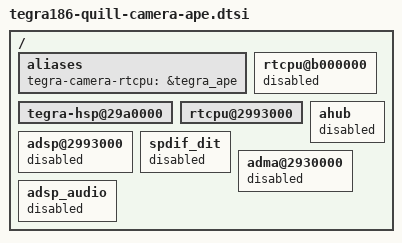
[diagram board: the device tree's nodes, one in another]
/*
 * tegra186-quill-camera-ape.dtsi: Quill APE for camera dtsi.
 *
 * Copyright (c) 2016, NVIDIA CORPORATION.  All rights reserved.
 *
 * This program is free software; you can redistribute it and/or modify
 * it under the terms of the GNU General Public License as published by
 * the Free Software Foundation; version 2 of the License.
 *
 * This program is distributed in the hope that it will be useful, but WITHOUT
 * ANY WARRANTY; without even the implied warranty of MERCHANTABILITY or
 * FITNESS FOR A PARTICULAR PURPOSE.  See the GNU General Public License for
 * more details.
 */

/ {
	aliases {
		tegra-camera-rtcpu = &tegra_ape;
	};

	tegra-hsp@29a0000 {
		status = "okay";
	};

	rtcpu@b000000 {	/* Do not use SCE as camera-rtcpu */
		status = "disabled";
	};

	rtcpu@2993000 {	/* use APE as camera-rtcpu */
		status = "okay";
	};

	adsp@2993000 {	/* Do not use APE as adsp */
		status = "disabled";
	};

	ahub {
		status = "disabled";
	};

	spdif_dit {
		status = "disabled";
	};

	adma@2930000 {
		status = "disabled";
	};

        adsp_audio {
		status = "disabled";
	};
};
